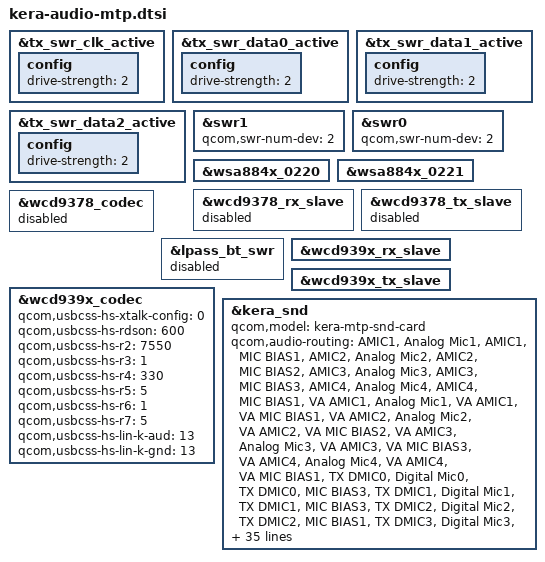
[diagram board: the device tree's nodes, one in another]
// SPDX-License-Identifier: BSD-3-Clause
/*
 * Copyright (c) 2023-2024 Qualcomm Innovation Center, Inc. All rights reserved.
 */

#include "kera-audio-overlay.dtsi"
#include "kera-audio-lpass-reg.dtsi"

&tx_swr_clk_active {
	config {
		drive-strength = <2>;
	};
};

&tx_swr_data0_active {
	config {
		drive-strength = <2>;
	};
};

&tx_swr_data1_active {
	config {
		drive-strength = <2>;
	};
};

&tx_swr_data2_active {
	config {
		drive-strength = <2>;
	};
};

&swr1 {
	qcom,swr-num-dev = <2>;
};

&swr0 {
	qcom,swr-num-dev = <2>;
};

&wsa884x_0220 {
	status = "okay";
};

&wsa884x_0221 {
	status = "okay";
};

&wcd9378_rx_slave {
	status = "disabled";
};

&wcd9378_tx_slave {
	status = "disabled";
};

&wcd9378_codec {
	status = "disabled";
};

&lpass_bt_swr {
	status = "disabled";
};

&wcd939x_rx_slave {
	status = "okay";
};

&wcd939x_tx_slave {
	status = "okay";
};

&wcd939x_codec {
	status = "okay";
	/* 0 for digital crosstalk disabled,
	 * 1 for digital crosstalk with local sensed a-xtalk enabled, and
	 * 2 for digital crosstalk with remote sensed a-xtalk enabled.
	 */
	qcom,usbcss-hs-xtalk-config = <0>;
	qcom,usbcss-hs-rdson = <600>;
	qcom,usbcss-hs-r2 = <7550>;
	qcom,usbcss-hs-r3 = <1>;
	qcom,usbcss-hs-r4 = <330>;
	qcom,usbcss-hs-r5 = <5>;
	qcom,usbcss-hs-r6 = <1>;
	qcom,usbcss-hs-r7 = <5>;
	qcom,usbcss-hs-lin-k-aud = <13>;
	qcom,usbcss-hs-lin-k-gnd = <13>;
};


&kera_snd {
	qcom,model = "kera-mtp-snd-card";
	qcom,audio-routing =
			"AMIC1", "Analog Mic1",
			"AMIC1", "MIC BIAS1",
			"AMIC2", "Analog Mic2",
			"AMIC2", "MIC BIAS2",
			"AMIC3", "Analog Mic3",
			"AMIC3", "MIC BIAS3",
			"AMIC4", "Analog Mic4",
			"AMIC4", "MIC BIAS1",
			"VA AMIC1", "Analog Mic1",
			"VA AMIC1", "VA MIC BIAS1",
			"VA AMIC2", "Analog Mic2",
			"VA AMIC2", "VA MIC BIAS2",
			"VA AMIC3", "Analog Mic3",
			"VA AMIC3", "VA MIC BIAS3",
			"VA AMIC4", "Analog Mic4",
			"VA AMIC4", "VA MIC BIAS1",
			"TX DMIC0", "Digital Mic0",
			"TX DMIC0", "MIC BIAS3",
			"TX DMIC1", "Digital Mic1",
			"TX DMIC1", "MIC BIAS3",
			"TX DMIC2", "Digital Mic2",
			"TX DMIC2", "MIC BIAS1",
			"TX DMIC3", "Digital Mic3",
			"TX DMIC3", "MIC BIAS1",
			"IN1_HPHL", "HPHL_OUT",
			"IN2_HPHR", "HPHR_OUT",
			"IN3_EAR", "AUX_OUT",
			"WSA SRC0_INP", "SRC0",
			"WSA_TX DEC0_INP", "TX DEC0 MUX",
			"WSA_TX DEC1_INP", "TX DEC1 MUX",
			"RX_TX DEC0_INP", "TX DEC0 MUX",
			"RX_TX DEC1_INP", "TX DEC1 MUX",
			"RX_TX DEC2_INP", "TX DEC2 MUX",
			"RX_TX DEC3_INP", "TX DEC3 MUX",
			"SpkrLeft IN", "WSA_SPK1 OUT",
			"SpkrRight IN", "WSA_SPK2 OUT",
			"TX SWR_INPUT", "WCD_TX_OUTPUT",
			"VA SWR_INPUT", "WCD_TX_OUTPUT",
			"VA SWR_INPUT", "VA_SWR_CLK",
			"VA_AIF1 CAP", "VA_SWR_CLK",
			"VA_AIF2 CAP", "VA_SWR_CLK",
			"VA_AIF3 CAP", "VA_SWR_CLK",
			"VA DMIC0", "Digital Mic0",
			"VA DMIC1", "Digital Mic1",
			"VA DMIC2", "Digital Mic2",
			"VA DMIC3", "Digital Mic3",
			"VA DMIC0", "VA MIC BIAS3",
			"VA DMIC1", "VA MIC BIAS3",
			"VA DMIC2", "VA MIC BIAS1",
			"VA DMIC3", "VA MIC BIAS1";
	qcom,cdc-dmic01-gpios = <&cdc_dmic01_gpios>;
	qcom,cdc-dmic23-gpios = <&cdc_dmic23_gpios>;
	qcom,msm_audio_ssr_devs = <&audio_gpr>, <&lpi_tlmm>,
				<&lpass_cdc>;
	asoc-codec  = <&stub_codec>, <&lpass_cdc>,
			<&wcd939x_codec>, <&wsa884x_0220>,
			<&wsa884x_0221>;
	asoc-codec-names = "msm-stub-codec.1", "lpass-cdc",
			"wcd939x_codec", "wsa-codec1",
			"wsa-codec2";
	qcom,wsa-max-devs = <2>;
	swr-haptics-unsupported;
	qcom,pri_mi2s_gpios = <&cdc_pri_mi2s_gpios>;
	qcom,wcd-disable-legacy-surge;
	wcd939x-i2c-handle = <&wcd_usbss>;
	qcom,msm-mbhc-usbc-audio-supported = <0>;
	qcom,msm-mbhc-hphl-swh = <1>;
	qcom,msm-mbhc-gnd-swh = <1>;
	qcom,msm-mbhc-hs-mic-max-threshold-mv = <1670>;
};
